# STM32H7P5 register map
File version: 2.0.0
CPU: CM7 r1p2, little endian, MPU, FPU, 4 interrupt priority bits
Registers are 32-bit, read-write, reset 0x0 unless marked. A register's access mark holds for its fields unless they carry their own. Offsets are from the block's base; [hi:lo] are bit positions; lines under a group give offsets from that group; {n}, {i} and the like mark numbered series; 'fields as' and 'values as' point back to an identical list.

## FLASH — FLASH register bank
Base 0x52002000
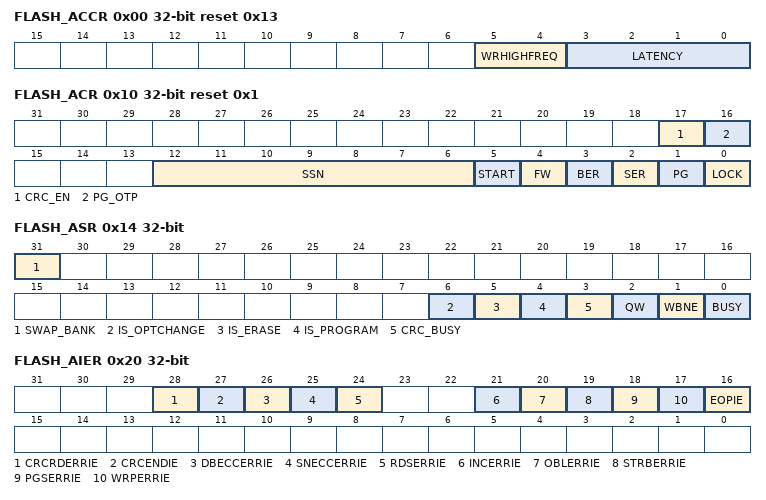
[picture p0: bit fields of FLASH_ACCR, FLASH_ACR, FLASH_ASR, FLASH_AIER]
0x00 FLASH_ACCR reset 0x13 — FLASH access control register
  [5:4] WRHIGHFREQ — Flash signal delay
  [3:0] LATENCY — Read latency
    0=Zero wait state used to read a word from non-volatile memory; 1=One wait state used to read a word from non-volatile memory; 2=Two wait states used to read a word from non-volatile memory; 15=Fifteen wait states used to read from non-volatile memory
0x04 FLASH_AKEYR wo — FLASH bank A control key register
  [31:0] CUKEY — Control unlock key
0x10 FLASH_ACR reset 0x1 — FLASH bank A control register
  [17] CRC_EN — CRC enable
  [16] PG_OTP — Program enable for OTP area
  [12:6] SSN — Sector erase selection number
    0=Sector 0; 1=Sector 1; 63=Sector 63; 64=Sector 64 (STM32H7PxI devices only); 127=Sector 127 (STM32H7PxI devices only)
  [5] START — Erase start control bit
  [4] FW wo — Force write
  [3] BER — Bank erase request
    0=Bank erase is not requested; 1=Bank erase is requested
  [2] SER — Sector erase request
    0=Sector erase not requested; 1=Sector erase requested
  [1] PG — Internal buffer control bit
    0=Internal buffer disabled for write operations; 1=Internal buffer enabled for write operations
  [0] LOCK — Configuration lock bit
    0=FLASH_xCR and FLASH_xIER registers are unlocked; 1=Writes to FLASH_xIER, and to other bits than LOCK in FLASH_xCR, are ignored
0x14 FLASH_ASR ro — FLASH bank A status register
  [31] SWAP_BANK — Swapped bank
    0=Physical bank 1 is allocated to the bank if x=A (bank 2 if x=B); 1=Physical bank 2 is allocated to the bank if x=A (bank 1 if x=B)
  [6] IS_OPTCHANGE — Is an option change
  [5] IS_ERASE — Is an erase
  [4] IS_PROGRAM — Is a program
  [3] CRC_BUSY — CRC busy flag
    0=No CRC calculation ongoing; 1=CRC calculation ongoing
  [2] QW — Wait queue flag
    0=No write, erase or option byte change operations waiting in the operation queues; 1=At least one write, erase or option byte change operation is waiting in the operation queue
  [1] WBNE — Write buffer not empty flag
    0=Write buffer empty or full; 1=Write buffer waiting data to complete
  [0] BUSY — Busy flag
    0=No programming, erase or option byte change operation are being executed; 1=Programming, erase or option byte change operation are being executed
0x20 FLASH_AIER — FLASH bank A interrupt enable register
  [28] CRCRDERRIE — CRC read error interrupt enable bit
    0=No interrupt is generated when CRCRDERRF bit is set in FLASH_xISR register; 1=An interrupt is generated when CRCRDERRF bit is set in FLASH_xISR register
  [27] CRCENDIE — CRC end of calculation interrupt enable bit
    0=No interrupt is generated when CRCEN bit is set in FLASH_xISR register; 1=An interrupt is generated when CRCEN bit is set in FLASH_xISR register
  [26] DBECCERRIE — ECC double detection error interrupt enable bit
    0=No interrupt is generated when DBECCERRF bit is set in FLASH_xISR register; 1=An interrupt is generated when DBECCERRF bit is set in FLASH_xISR register
  [25] SNECCERRIE — ECC single correction error interrupt enable bit
    0=No interrupt is generated when SNECCERRF bit is set in FLASH_xISR register; 1=An interrupt is generated when SNECCERRF bit is set in FLASH_xISR register
  [24] RDSERRIE — Read security error interrupt enable bit
    0=No interrupt is generated when RDSERRF bit is set in FLASH_xISR register; 1=An interrupt is generated when RDSERRF bit is set in FLASH_xISR register
  [21] INCERRIE — Inconsistency error interrupt enable bit
    0=No interrupt is generated when INCERRF bit is set in FLASH_xISR register; 1=An interrupt is generated when INCERRF bit is set in FLASH_xISR register
  [20] OBLERRIE — Option byte loading error interrupt enable bit
    0=No interrupt is generated when OBLERRF bit is set in FLASH_xISR register; 1=An interrupt is generated when OBLERRF bit is set in FLASH_xISR register
  [19] STRBERRIE — Strobe error interrupt enable bit
    0=No interrupt is generated when STRBERRF bit is set in FLASH_xISR register; 1=An interrupt is generated when STRBERRF bit is set in FLASH_xISR register
  [18] PGSERRIE — Programming sequence error interrupt enable bit
    0=No interrupt is generated when PGSERRF bit is set in FLASH_xISR register; 1=An interrupt is generated when PGSERRF bit is set in FLASH_xISR register
  [17] WRPERRIE — Write protection error interrupt enable bit
    0=No interrupt is generated when WRPERRF bit is set in FLASH_xISR register; 1=An interrupt is generated when WRPERRF bit is set in FLASH_xISR register
  [16] EOPIE — End-of-program interrupt control bit
    0=No interrupt is generated when OEPF bit is set in FLASH_xISR register; 1=An interrupt is generated when OEPF bit is set in FLASH_xISR register
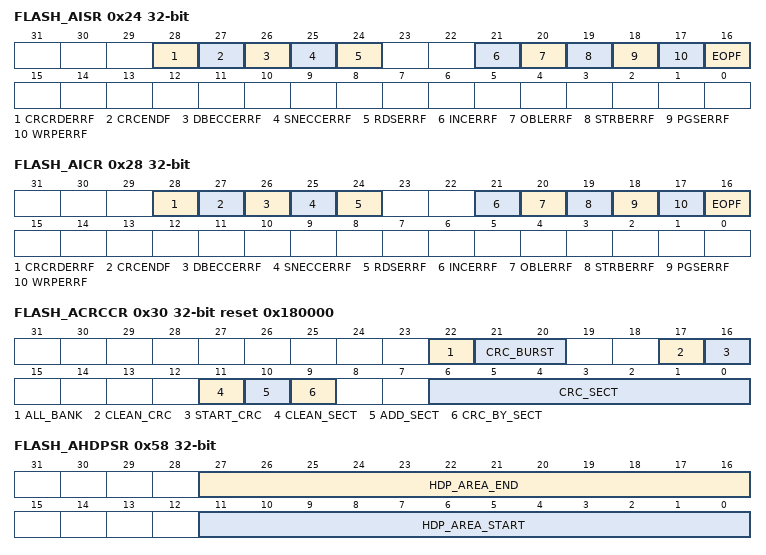
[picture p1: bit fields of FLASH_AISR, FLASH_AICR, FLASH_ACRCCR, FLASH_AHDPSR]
0x24 FLASH_AISR ro — FLASH bank A interrupt status register
  [28] CRCRDERRF — CRC read error flag
    0=No protected area detected inside addresses read by CRC; 1=At least one protected area has been detected inside address read by CRC
  [27] CRCENDF — CRC end flag
    0=CRC computation not complete; 1=CRC computation complete
  [26] DBECCERRF — ECC double error flag
    0=No ECC double detection error occurred; 1=ECC double detection error occurred
  [25] SNECCERRF — ECC single error flag
    0=No ECC single correction error occurred; 1=ECC single correction error occurred
  [24] RDSERRF — Read security error flag
    0=No security error occurred; 1=A security error occurred
  [21] INCERRF — Inconsistency error flag
    0=No inconsistency error occurred; 1=A inconsistency error occurred
  [20] OBLERRF — Option byte loading error flag
    0=No error found during option byte loading sequence; 1=Some errors found during option byte loading sequence
  [19] STRBERRF — Strobe error flag
    0=No strobe error occurred; 1=Astrobe error occurred
  [18] PGSERRF — Programming sequence error flag
    0=No sequence error occurred; 1=Asequence error occurred
  [17] WRPERRF — Write protection error flag
    0=No write protection error occurred; 1=A write protection error occurred
  [16] EOPF — End-of-program flag
    0=No programming or erase operation completed; 1=Programming, or erasing operation completed
0x28 FLASH_AICR wo — FLASH bank A interrupt clear register
  [28] CRCRDERRF — CRC error flag clear
  [27] CRCENDF — CRC end flag clear
  [26] DBECCERRF — ECC double error flag clear
  [25] SNECCERRF — ECC single error flag clear
  [24] RDSERRF — Read security error flag clear
  [21] INCERRF — Inconsistency error flag clear
  [20] OBLERRF — Option byte loading error flag clear
  [19] STRBERRF — Strobe error flag clear
  [18] PGSERRF — Programming sequence error flag clear
  [17] WRPERRF — Write protection error flag clear
  [16] EOPF — End-of-program flag clear
0x30 FLASH_ACRCCR reset 0x180000 — FLASH bank A CRC control register
  [22] ALL_BANK wo — All sectors in bank selection
  [21:20] CRC_BURST — CRC burst size
    0=every burst has a size of 4 flash words (64 Bytes); 1=every burst has a size of 16 flash words (256 Bytes); 2=every burst has a size of 64 flash words (1 Kbytes); 3=every burst has a size of 256 flash words (4 Kbytes)
  [17] CLEAN_CRC wo — CRC clear bit
  [16] START_CRC — CRC start bit
  [11] CLEAN_SECT wo — CRC sector list clear bit
  [10] ADD_SECT wo — CRC sector select bit
  [9] CRC_BY_SECT — CRC sector mode select bit
  [6:0] CRC_SECT — CRC sector number
    0=sector 0 for CRC; 1=sector 1 for CRC; 63=sector 63 for CRC; 127=sector 127 for CRC (STM32H7PxI devices only)
0x34 FLASH_ACRCSADDR — FLASH bank A CRC start address register
  [19:2] CRC_START_ADDR — CRC start address
0x38 FLASH_ACRCEADDR — FLASH bank A CRC end address register
  [19:2] CRC_END_ADDR — CRC end address
0x3C FLASH_CRCDATAR ro — FLASH CRC data register
  [31:0] CRC_DATA — CRC result
0x40 FLASH_AECCSFADDR ro — FLASH bank A ECC single error fail address
  [31:0] SEC_FADD — ECC single error correction fail address
0x44 FLASH_AECCDFADDR ro — FLASH bank A ECC double error fail address
  [31:0] DED_FADD — ECC double error detection fail address
0x50 FLASH_AWRPSR ro reset not defined — FLASH bank A write protection status register
  [31:0] WRPSG — Write protection for sector group n in bank x
0x54 FLASH_AWRPSRP reset not defined — FLASH bank A write protection status register programming
  [31:0] WRPSG — Write protection for sector group n in bank x programming
0x58 FLASH_AHDPSR ro (reset mask 0xF000F000) — FLASH bank A hide protection status register
  [27:16] HDP_AREA_END — Hide protection user flash area end for bank x
  [11:0] HDP_AREA_START — Hide protection user flash area start for bank x
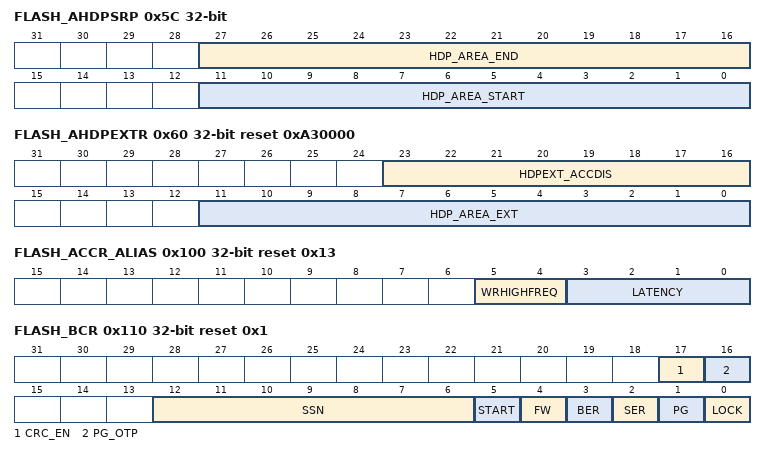
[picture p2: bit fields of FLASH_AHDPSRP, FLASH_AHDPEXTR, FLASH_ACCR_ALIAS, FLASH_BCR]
0x5C FLASH_AHDPSRP (reset mask 0xF000FFFF) — FLASH bank A hide protection status register programming
  [27:16] HDP_AREA_END — Hide protection user flash area end programming for bank x
  [11:0] HDP_AREA_START — Hide protection user flash area start programming for bank x
0x60 FLASH_AHDPEXTR reset 0xA30000 — FLASH bank A HDP extension register
  [23:16] HDPEXT_ACCDIS — HDP extension area access disable for bank x
    163=HDP extension area is not active and can be configured with HDP_AREA_EXT[11:0]; 92=HDP extension area is active, and can be increased (not decreased) with HDP_AREA_EXT[11:0]
  [11:0] HDP_AREA_EXT — HDP extension area end for bank x
0x100 FLASH_ACCR_ALIAS reset 0x13 — FLASH access control register
  fields as FLASH_ACCR
0x104 FLASH_BKEYR wo — FLASH bank B control key register
  [31:0] CUKEY — Control unlock key
0x110 FLASH_BCR reset 0x1 — FLASH bank B control register
  fields as FLASH_ACR
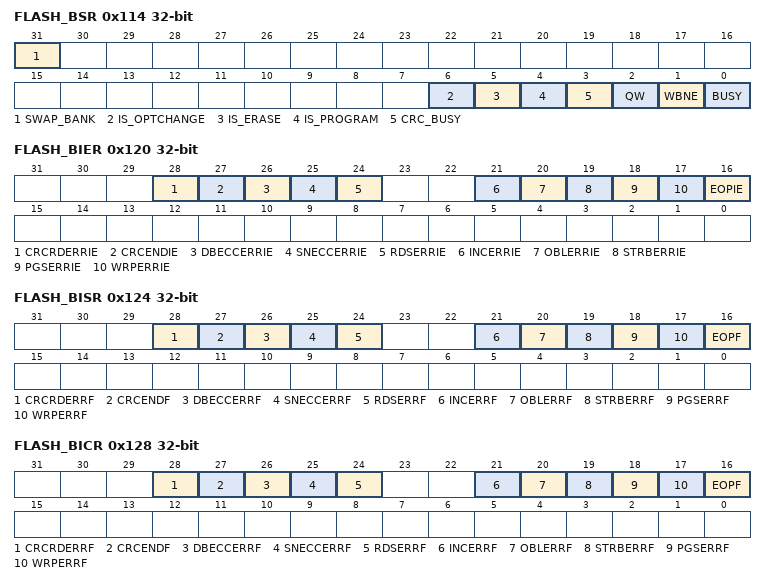
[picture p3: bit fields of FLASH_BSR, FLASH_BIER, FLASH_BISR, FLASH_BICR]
0x114 FLASH_BSR ro — FLASH bank B status register
  fields as FLASH_ASR
0x120 FLASH_BIER — FLASH bank B interrupt enable register
  fields as FLASH_AIER
0x124 FLASH_BISR ro — FLASH bank B interrupt status register
  fields as FLASH_AISR
0x128 FLASH_BICR wo — FLASH bank B interrupt clear register
  fields as FLASH_AICR
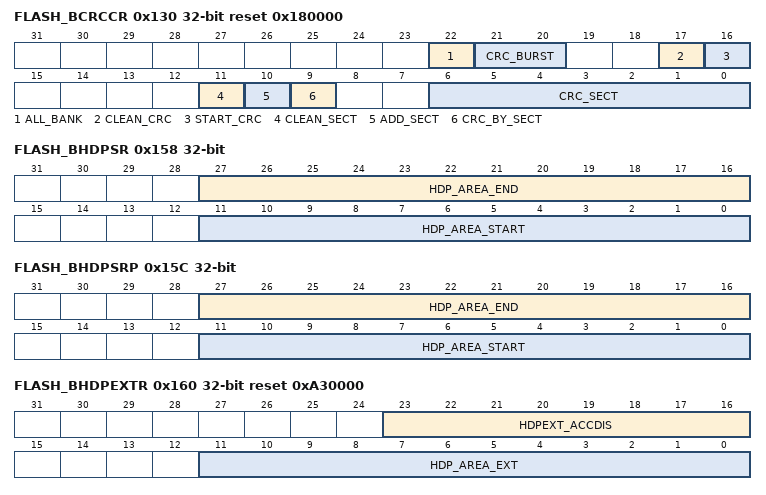
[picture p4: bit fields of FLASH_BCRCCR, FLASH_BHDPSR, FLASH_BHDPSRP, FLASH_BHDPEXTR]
0x130 FLASH_BCRCCR reset 0x180000 — FLASH bank B CRC control register
  fields as FLASH_ACRCCR
0x134 FLASH_BCRCSADDR — FLASH bank B CRC start address register
  [19:2] CRC_START_ADDR — CRC start address
0x138 FLASH_BCRCEADDR — FLASH bank B CRC end address register
  [19:2] CRC_END_ADDR — CRC end address
0x13C FLASH_CRCDATAR_ALIAS ro — FLASH CRC data register
  [31:0] CRC_DATA — CRC result
0x140 FLASH_BECCSFADDR ro — FLASH bank B ECC single error fail address
  [31:0] SEC_FADD — ECC single error correction fail address
0x144 FLASH_BECCDFADDR ro — FLASH bank B ECC double error fail address
  [31:0] DED_FADD — ECC double error detection fail address
0x150 FLASH_BWRPSR ro reset not defined — FLASH bank B write protection status register
  [31:0] WRPSG — Write protection for sector group n in bank x
0x154 FLASH_BWRPSRP reset not defined — FLASH bank B write protection status register programming
  fields as FLASH_AWRPSRP
0x158 FLASH_BHDPSR ro (reset mask 0xF000F000) — FLASH bank B hide protection status register
  fields as FLASH_AHDPSR
0x15C FLASH_BHDPSRP (reset mask 0xF000FFFF) — FLASH bank B hide protection status register programming
  fields as FLASH_AHDPSRP
0x160 FLASH_BHDPEXTR reset 0xA30000 — FLASH bank B HDP extension register
  fields as FLASH_AHDPEXTR
0x200 FLASH_OPTKEYR wo — FLASH options key register
  [31:0] OCUKEY — Options configuration unlock key
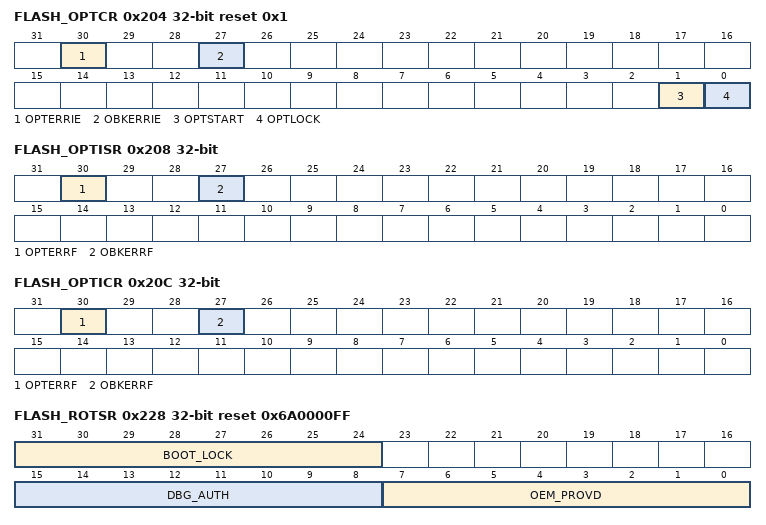
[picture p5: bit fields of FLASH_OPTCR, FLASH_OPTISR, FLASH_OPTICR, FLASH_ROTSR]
0x204 FLASH_OPTCR reset 0x1 (reset mask 0xFFFFFFF) — FLASH options control register
  [30] OPTERRIE — Option byte change error interrupt enable bit
    0=No interrupt is generated when an error occurs during an option byte change; 1=An interrupt is generated when and error occurs during an option byte change
  [27] OBKERRIE — Option byte key error interrupt enable bit
    0=No interrupt is generated when an OBkey error occurs; 1=An interrupt is generated when an OBkey error occurs
  [1] OPTSTART wo — Options update start
    0=No action or option byte change acknowledged; 1=Option byte change requested
  [0] OPTLOCK — Options lock
    0=OTP words, FLASH_OPTCR, and FLASH_xSRP registers are unlocked; 1=Writes to OTP words, FLASH_xSRP and to other bits than OPTLOCK in FLASH_OPTCR, are ignored
0x208 FLASH_OPTISR ro reset not defined — FLASH options interrupt status register
  [30] OPTERRF — Option byte change error flag
    0=No option byte change errors occurred; 1=One or more errors occurred during an option byte change operation
  [27] OBKERRF — Option byte key error flag
    0=No option byte key reading or programming error occurred; 1=A double error detection was found when loading the requested option byte key, or the programming of a non-virgin key was detected during the last programming operation
0x20C FLASH_OPTICR wo reset not defined — FLASH options interrupt clear register
  [30] OPTERRF — Option byte change error flag
  [27] OBKERRF — Option byte key error flag
0x210 FLASH_OTPLSR ro — FLASH OTP lock status register
  [15:0] OTPL — OTP lock n
0x214 FLASH_OTPLSRP — FLASH OTP lock status register programming
  [15:0] OTPL — OTP lock n programming
0x220 FLASH_NVSR ro reset 0xFF — FLASH non-volatile status register
  [7:0] NVSTATE — Non-volatile state
    180=NVOPEN; 81=NVCLOSED (default)
0x224 FLASH_NVSRP reset 0xFF — FLASH security status register programming
  [7:0] NVSTATE — Non-volatile state programming
    180=NVOPEN; 81=NVCLOSE
0x228 FLASH_ROTSR ro reset 0x6A0000FF — FLASH RoT status register
  [31:24] BOOT_LOCK
    180=Change to SWAP_BANK option bit is always ignored (default); 106=Change to SWAP_BANK option bit is allowed
  [15:8] DBG_AUTH — Debug authentication method
    180=No debug allowed, no regression (Locked device) (default); 138=No debug allowed, regression with password (Closed device); 111=No debug out of reset, regression with password (Closed device)
  [7:0] OEM_PROVD — OEM provisioned device
    180=Device has been provisioned by the OEM; 106=Device is not provisioned by the OEM (default)
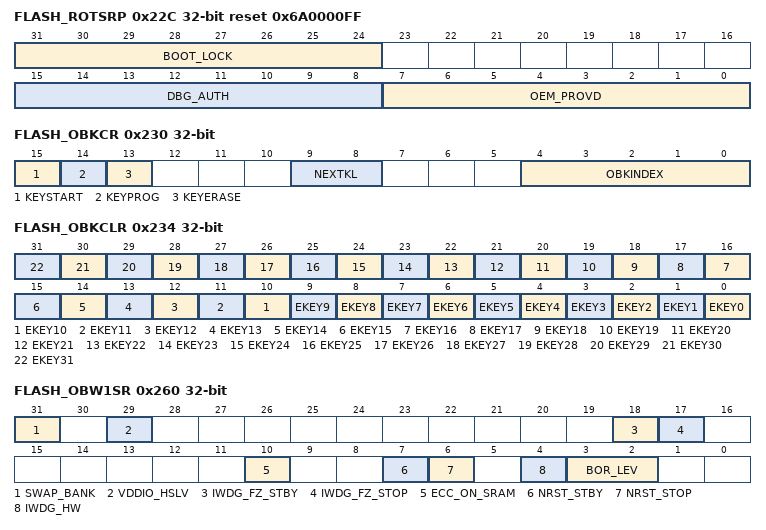
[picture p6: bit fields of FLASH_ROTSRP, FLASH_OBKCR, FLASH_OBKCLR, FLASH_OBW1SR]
0x22C FLASH_ROTSRP reset 0x6A0000FF — FLASH RoT status register programming
  [31:24] BOOT_LOCK — Boot lock programming
  [15:8] DBG_AUTH — Debug authentication method programming
  [7:0] OEM_PROVD — OEM provisioned device
0x230 FLASH_OBKCR — FLASH option byte key control register
  [15] KEYSTART — Key option start
  [14] KEYPROG — Key program
    0=Read key; 1=Write key stored in FLASH_OBKDRx registers
  [13] KEYERASE
    0=No action; 1=Erase keys
  [9:8] NEXTKL — Next key level
    0=OBKINDEX represents the index of the option byte key stored for the hide protection level indicated in SBS_HDPLSR; 1=OBKINDEX represents the index of the option byte key stored for the hide protection level indicated in SBS_HDPLSR plus one (for example if HDPL=1 in SBS_HDPLR the key of level 2 is selected)
  [4:0] OBKINDEX — Option byte key index
0x234 FLASH_OBKCLR — FLASH option byte key clear register
  [n] EKEY{n} (n=0..31) — Erase key {n}
{0x240+4i} FLASH_OBKDR{i} (i=0..3) — FLASH option bytes key data register {i}
  [31:0] OBKDATA — option byte key data, bits [31+x:0+x]
0x260 FLASH_OBW1SR ro reset not defined — FLASH option byte word 1 status register
  [31] SWAP_BANK — Bank swapping
    0=Following a system or power-on-reset both SWAP_BANK bits are cleared in FLASH_xSR registers (see Section1; 1=Following a system or power-on-reset both SWAP_BANK bits are set in FLASH_xSR registers (see Section1
  [29] VDDIO_HSLV — I/O high-speed at low-voltage
    0=Product working in the full voltage range, I/O speed optimization at low-voltage disabled; 1=Product operating below 2
  [18] IWDG_FZ_STBY — IWDG standby mode freeze
    0=Independent watchdog frozen in Standby mode; 1=Independent watchdog keep running in Standby mode
  [17] IWDG_FZ_STOP — IWDG stop mode freeze
    0=Independent watchdog frozen in Stop mode; 1=Independent watchdog keep running in Stop mode
  [10] ECC_ON_SRAM
    0=ECC on SRAM option disabled (default TBC); 1=ECC on SRAM option enabled
  [7] NRST_STBY — Reset on standby mode
    0=Independent WDG generates a reset if STANDBY mode is requested; 1=Independent WDG does not generate a reset if STANDBY mode is requested (default TBC)
  [6] NRST_STOP — Reset on stop mode
    0=Independent WDG generates a reset if STOP mode is requested; 1=Independent WDG does not generate a reset if STOP mode is requested (default TBC)
  [4] IWDG_HW — Independent watchdog HW Control
    1=IWDG watchdog is controlled by software (default TBC); 0=IWDG watchdog is controller by hardware
  [3:2] BOR_LEV — Brownout level
    0=BOR OFF, POR/PDR reset threshold level is applied (default TBC); 1=BOR Level 1, the threshold level is low (around 2; 2=BOR Level 2, the threshold level is medium (around 2; 3=BOR Level 3, the threshold level is high (around 2
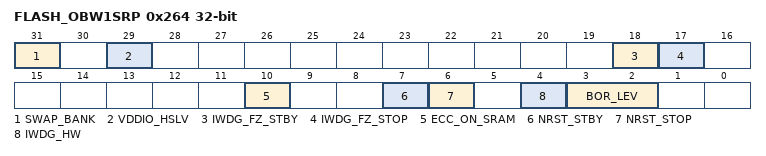
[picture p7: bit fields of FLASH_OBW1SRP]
0x264 FLASH_OBW1SRP reset not defined — FLASH option byte word 1 status register programming
  [31] SWAP_BANK — Bank swapping programming
  [29] VDDIO_HSLV — I/O high-speed at low-voltage programming
  [18] IWDG_FZ_STBY — IWDG standby mode freeze programming
  [17] IWDG_FZ_STOP — IWDG stop mode freeze
  [10] ECC_ON_SRAM
  [7] NRST_STBY — Reset on standby mode programming
  [6] NRST_STOP — Reset on stop mode programming
  [4] IWDG_HW — Independent watchdog HW Control
  [3:2] BOR_LEV — Brownout level
